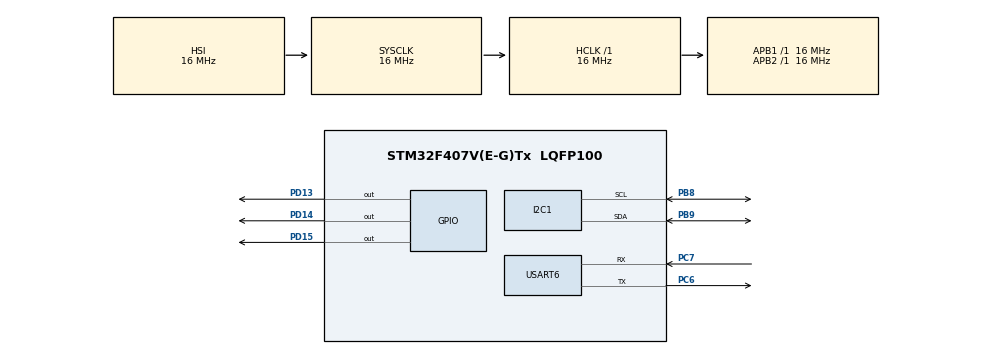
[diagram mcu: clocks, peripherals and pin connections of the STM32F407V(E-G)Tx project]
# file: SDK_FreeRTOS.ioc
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FREERTOS.Queues01=myKbdQueue,8,uint8_t,0,Dynamic,NULL,NULL
FREERTOS.Tasks01=Task_LED1,0,128,StartTaskLED1,Default,NULL,Dynamic,NULL,NULL;myTaskTetris,0,512,StartTaskTetris,Default,NULL,Dynamic,NULL,NULL;myTaskKbd,0,512,StartTaskKbd,Default,NULL,Dynamic,NULL,NULL
FREERTOS.configENABLE_BACKWARD_COMPATIBILITY=0
FREERTOS.configGENERATE_RUN_TIME_STATS=1
FREERTOS.configUSE_NEWLIB_REENTRANT=1
FREERTOS.configUSE_STATS_FORMATTING_FUNCTIONS=1
FREERTOS.configUSE_TRACE_FACILITY=1
Mcu.Family=STM32F4
Mcu.Name=STM32F407V(E-G)Tx
Mcu.Package=LQFP100
NVIC.PriorityGroup=NVIC_PRIORITYGROUP_4
NVIC.TIM1_UP_TIM10_IRQn=true\:0\:0\:false\:false\:true\:false\:false\:true\:true
NVIC.TimeBase=TIM1_UP_TIM10_IRQn
NVIC.TimeBaseIP=TIM1
PA13.Mode=JTAG_5_pins
PA13.Signal=SYS_JTMS-SWDIO
PA14.Mode=JTAG_5_pins
PA14.Signal=SYS_JTCK-SWCLK
PA15.Mode=JTAG_5_pins
PA15.Signal=SYS_JTDI
PB3.Mode=JTAG_5_pins
PB3.Signal=SYS_JTDO-SWO
PB4.Mode=JTAG_5_pins
PB4.Signal=SYS_JTRST
PB8.Mode=I2C
PB8.Signal=I2C1_SCL
PB9.Mode=I2C
PB9.Signal=I2C1_SDA
PC6.Mode=Asynchronous
PC6.Signal=USART6_TX
PC7.Mode=Asynchronous
PC7.Signal=USART6_RX
PD13.Signal=GPIO_Output
PD14.Signal=GPIO_Output
PD15.Signal=GPIO_Output
PH0-OSC_IN.Mode=HSE-External-Oscillator
PH0-OSC_IN.Signal=RCC_OSC_IN
PH1-OSC_OUT.Mode=HSE-External-Oscillator
PH1-OSC_OUT.Signal=RCC_OSC_OUT
ProjectManager.HeapSize=0x200
ProjectManager.StackSize=0x400
ProjectManager.TargetToolchain=STM32CubeIDE
RCC.AHBFreq_Value=16000000
RCC.APB1Freq_Value=16000000
RCC.APB2Freq_Value=16000000
RCC.CortexFreq_Value=16000000
RCC.HSE_VALUE=25000000
RCC.HSI_VALUE=16000000
RCC.LSE_VALUE=32768
RCC.SYSCLKFreq_VALUE=16000000
RCC.VCOOutputFreq_Value=192000000
USART6.VirtualMode=VM_ASYNC
VP_FREERTOS_VS_CMSIS_V1.Mode=CMSIS_V1
VP_RNG_VS_RNG.Mode=RNG_Activate
VP_SYS_VS_tim1.Mode=TIM1
board=custom

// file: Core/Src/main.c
/* USER CODE BEGIN Header */
/**
  ******************************************************************************
  * @file           : main.c
  * @brief          : Main program body
  ******************************************************************************
  * This notice applies to any and all portions of this file
  * that are not between comment pairs USER CODE BEGIN and
  * USER CODE END. Other portions of this file, whether
  * inserted by the user or by software development tools
  * are owned by their respective copyright owners.
  *
  * Copyright (c) 2019 STMicroelectronics International N.V.
  * All rights reserved.
  *
  * Redistribution and use in source and binary forms, with or without
  * modification, are permitted, provided that the following conditions are met:
  *
  * 1. Redistribution of source code must retain the above copyright notice,
  *    this list of conditions and the following disclaimer.
  * 2. Redistributions in binary form must reproduce the above copyright notice,
  *    this list of conditions and the following disclaimer in the documentation
  *    and/or other materials provided with the distribution.
  * 3. Neither the name of STMicroelectronics nor the names of other
  *    contributors to this software may be used to endorse or promote products
  *    derived from this software without specific written permission.
  * 4. This software, including modifications and/or derivative works of this
  *    software, must execute solely and exclusively on microcontroller or
  *    microprocessor devices manufactured by or for STMicroelectronics.
  * 5. Redistribution and use of this software other than as permitted under
  *    this license is void and will automatically terminate your rights under
  *    this license.
  *
  * THIS SOFTWARE IS PROVIDED BY STMICROELECTRONICS AND CONTRIBUTORS "AS IS"
  * AND ANY EXPRESS, IMPLIED OR STATUTORY WARRANTIES, INCLUDING, BUT NOT
  * LIMITED TO, THE IMPLIED WARRANTIES OF MERCHANTABILITY, FITNESS FOR A
  * PARTICULAR PURPOSE AND NON-INFRINGEMENT OF THIRD PARTY INTELLECTUAL PROPERTY
  * RIGHTS ARE DISCLAIMED TO THE FULLEST EXTENT PERMITTED BY LAW. IN NO EVENT
  * SHALL STMICROELECTRONICS OR CONTRIBUTORS BE LIABLE FOR ANY DIRECT, INDIRECT,
  * INCIDENTAL, SPECIAL, EXEMPLARY, OR CONSEQUENTIAL DAMAGES (INCLUDING, BUT NOT
  * LIMITED TO, PROCUREMENT OF SUBSTITUTE GOODS OR SERVICES; LOSS OF USE, DATA,
  * OR PROFITS; OR BUSINESS INTERRUPTION) HOWEVER CAUSED AND ON ANY THEORY OF
  * LIABILITY, WHETHER IN CONTRACT, STRICT LIABILITY, OR TORT (INCLUDING
  * NEGLIGENCE OR OTHERWISE) ARISING IN ANY WAY OUT OF THE USE OF THIS SOFTWARE,
  * EVEN IF ADVISED OF THE POSSIBILITY OF SUCH DAMAGE.
  *
  ******************************************************************************
  */
/* USER CODE END Header */
#include "main.h"
#include "cmsis_os.h"
#include "i2c.h"
#include "rng.h"
#include "usart.h"
#include "gpio.h"

/* USER CODE BEGIN Includes */
#include "oled.h"
/* USER CODE END Includes */

void SystemClock_Config(void);
void MX_FREERTOS_Init(void);

int main(void)
{

  /* MCU Configuration--------------------------------------------------------*/

  /* Reset of all peripherals, Initializes the Flash interface and the Systick. */
  HAL_Init();

  /* Configure the system clock */
  SystemClock_Config();

  /* Initialize all configured peripherals */
  MX_GPIO_Init();
  MX_I2C1_Init();
  MX_USART6_UART_Init();
  MX_RNG_Init();
  /* USER CODE BEGIN 2 */
  oled_Init();

  oled_Fill(Black);
  oled_UpdateScreen();
  /* USER CODE END 2 */

  /* Call init function for freertos objects (in cmsis_os2.c) */
  MX_FREERTOS_Init();

  /* Start scheduler */
  osKernelStart();

  /* We should never get here as control is now taken by the scheduler */

  /* Infinite loop */
  while (1)
  {

  }
}

void SystemClock_Config(void)
{
  RCC_OscInitTypeDef RCC_OscInitStruct = {0};
  RCC_ClkInitTypeDef RCC_ClkInitStruct = {0};

  /** Configure the main internal regulator output voltage
  */
  __HAL_RCC_PWR_CLK_ENABLE();
  __HAL_PWR_VOLTAGESCALING_CONFIG(PWR_REGULATOR_VOLTAGE_SCALE1);

  /** Initializes the RCC Oscillators according to the specified parameters
  * in the RCC_OscInitTypeDef structure.
  */
  RCC_OscInitStruct.OscillatorType = RCC_OSCILLATORTYPE_HSI;
  RCC_OscInitStruct.HSIState = RCC_HSI_ON;
  RCC_OscInitStruct.HSICalibrationValue = RCC_HSICALIBRATION_DEFAULT;
  RCC_OscInitStruct.PLL.PLLState = RCC_PLL_ON;
  RCC_OscInitStruct.PLL.PLLSource = RCC_PLLSOURCE_HSI;
  RCC_OscInitStruct.PLL.PLLM = 16;
  RCC_OscInitStruct.PLL.PLLN = 192;
  RCC_OscInitStruct.PLL.PLLP = RCC_PLLP_DIV2;
  RCC_OscInitStruct.PLL.PLLQ = 4;
  if (HAL_RCC_OscConfig(&RCC_OscInitStruct) != HAL_OK)
  {
    Error_Handler();
  }

  /** Initializes the CPU, AHB and APB buses clocks
  */
  RCC_ClkInitStruct.ClockType = RCC_CLOCKTYPE_HCLK|RCC_CLOCKTYPE_SYSCLK
                              |RCC_CLOCKTYPE_PCLK1|RCC_CLOCKTYPE_PCLK2;
  RCC_ClkInitStruct.SYSCLKSource = RCC_SYSCLKSOURCE_HSI;
  RCC_ClkInitStruct.AHBCLKDivider = RCC_SYSCLK_DIV1;
  RCC_ClkInitStruct.APB1CLKDivider = RCC_HCLK_DIV1;
  RCC_ClkInitStruct.APB2CLKDivider = RCC_HCLK_DIV1;

  if (HAL_RCC_ClockConfig(&RCC_ClkInitStruct, FLASH_LATENCY_0) != HAL_OK)
  {
    Error_Handler();
  }
}

void HAL_TIM_PeriodElapsedCallback(TIM_HandleTypeDef *htim)
{
  if (htim->Instance == TIM1)
  {
    HAL_IncTick();
  }
}

void Error_Handler(void)
{
}

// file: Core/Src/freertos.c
/* USER CODE BEGIN Header */
/**
  ******************************************************************************
  * File Name          : freertos.c
  * Description        : Code for freertos applications
  ******************************************************************************
  * This notice applies to any and all portions of this file
  * that are not between comment pairs USER CODE BEGIN and
  * USER CODE END. Other portions of this file, whether
  * inserted by the user or by software development tools
  * are owned by their respective copyright owners.
  *
  * Copyright (c) 2019 STMicroelectronics International N.V.
  * All rights reserved.
  *
  * Redistribution and use in source and binary forms, with or without
  * modification, are permitted, provided that the following conditions are met:
  *
  * 1. Redistribution of source code must retain the above copyright notice,
  *    this list of conditions and the following disclaimer.
  * 2. Redistributions in binary form must reproduce the above copyright notice,
  *    this list of conditions and the following disclaimer in the documentation
  *    and/or other materials provided with the distribution.
  * 3. Neither the name of STMicroelectronics nor the names of other
  *    contributors to this software may be used to endorse or promote products
  *    derived from this software without specific written permission.
  * 4. This software, including modifications and/or derivative works of this
  *    software, must execute solely and exclusively on microcontroller or
  *    microprocessor devices manufactured by or for STMicroelectronics.
  * 5. Redistribution and use of this software other than as permitted under
  *    this license is void and will automatically terminate your rights under
  *    this license.
  *
  * THIS SOFTWARE IS PROVIDED BY STMICROELECTRONICS AND CONTRIBUTORS "AS IS"
  * AND ANY EXPRESS, IMPLIED OR STATUTORY WARRANTIES, INCLUDING, BUT NOT
  * LIMITED TO, THE IMPLIED WARRANTIES OF MERCHANTABILITY, FITNESS FOR A
  * PARTICULAR PURPOSE AND NON-INFRINGEMENT OF THIRD PARTY INTELLECTUAL PROPERTY
  * RIGHTS ARE DISCLAIMED TO THE FULLEST EXTENT PERMITTED BY LAW. IN NO EVENT
  * SHALL STMICROELECTRONICS OR CONTRIBUTORS BE LIABLE FOR ANY DIRECT, INDIRECT,
  * INCIDENTAL, SPECIAL, EXEMPLARY, OR CONSEQUENTIAL DAMAGES (INCLUDING, BUT NOT
  * LIMITED TO, PROCUREMENT OF SUBSTITUTE GOODS OR SERVICES; LOSS OF USE, DATA,
  * OR PROFITS; OR BUSINESS INTERRUPTION) HOWEVER CAUSED AND ON ANY THEORY OF
  * LIABILITY, WHETHER IN CONTRACT, STRICT LIABILITY, OR TORT (INCLUDING
  * NEGLIGENCE OR OTHERWISE) ARISING IN ANY WAY OUT OF THE USE OF THIS SOFTWARE,
  * EVEN IF ADVISED OF THE POSSIBILITY OF SUCH DAMAGE.
  *
  ******************************************************************************
  */
/* USER CODE END Header */

#include "FreeRTOS.h"
#include "task.h"
#include "main.h"
#include "cmsis_os.h"

/* USER CODE BEGIN Includes */
#include "usart.h"
#include <string.h>
#include "tetris_task.h"
#include "kbd_task.h"
/* USER CODE END Includes */

osThreadId Task_LED1Handle;
osThreadId myTaskTetrisHandle;
osThreadId myTaskKbdHandle;
osMessageQId myKbdQueueHandle;

void StartTaskLED1(void const * argument);
void StartTaskTetris(void const * argument);
void StartTaskKbd(void const * argument);

void MX_FREERTOS_Init(void); /* (MISRA C 2004 rule 8.1) */

/* GetIdleTaskMemory prototype (linked to static allocation support) */
void vApplicationGetIdleTaskMemory( StaticTask_t **ppxIdleTaskTCBBuffer, StackType_t **ppxIdleTaskStackBuffer, uint32_t *pulIdleTaskStackSize );

/* Hook prototypes */
void configureTimerForRunTimeStats(void);
unsigned long getRunTimeCounterValue(void);

/* USER CODE BEGIN 1 */
/* Functions needed when configGENERATE_RUN_TIME_STATS is on */
__weak void configureTimerForRunTimeStats(void)
{

}

__weak unsigned long getRunTimeCounterValue(void)
{
return 0;
}
/* USER CODE END 1 */

/* USER CODE BEGIN GET_IDLE_TASK_MEMORY */
static StaticTask_t xIdleTaskTCBBuffer;
static StackType_t xIdleStack[configMINIMAL_STACK_SIZE];

void vApplicationGetIdleTaskMemory( StaticTask_t **ppxIdleTaskTCBBuffer, StackType_t **ppxIdleTaskStackBuffer, uint32_t *pulIdleTaskStackSize )
{
  *ppxIdleTaskTCBBuffer = &xIdleTaskTCBBuffer;
  *ppxIdleTaskStackBuffer = &xIdleStack[0];
  *pulIdleTaskStackSize = configMINIMAL_STACK_SIZE;
  /* place for user code */
}
/* USER CODE END GET_IDLE_TASK_MEMORY */

void MX_FREERTOS_Init(void) {

  /* Create the queue(s) */
  /* definition and creation of myKbdQueue */
  osMessageQDef(myKbdQueue, 8, uint8_t);
  myKbdQueueHandle = osMessageCreate(osMessageQ(myKbdQueue), NULL);

  /* Create the thread(s) */
  /* definition and creation of Task_LED1 */
  osThreadDef(Task_LED1, StartTaskLED1, osPriorityNormal, 0, 128);
  Task_LED1Handle = osThreadCreate(osThread(Task_LED1), NULL);

  /* definition and creation of myTaskTetris */
  osThreadDef(myTaskTetris, StartTaskTetris, osPriorityNormal, 0, 512);
  myTaskTetrisHandle = osThreadCreate(osThread(myTaskTetris), NULL);

  /* definition and creation of myTaskKbd */
  osThreadDef(myTaskKbd, StartTaskKbd, osPriorityNormal, 0, 512);
  myTaskKbdHandle = osThreadCreate(osThread(myTaskKbd), NULL);

}

void StartTaskLED1(void const * argument)
{
  /* USER CODE BEGIN StartTaskLED1 */
  /* Infinite loop */
  for(;;)
  {
	  HAL_GPIO_TogglePin(GPIOD, GPIO_PIN_15);
	  osDelay(600);
  }
  /* USER CODE END StartTaskLED1 */
}

void StartTaskTetris(void const * argument)
{
  /* USER CODE BEGIN StartTaskTetris */
  /* Infinite loop */
	Tetris_Task(argument);
  /* USER CODE END StartTaskTetris */
}

void StartTaskKbd(void const * argument)
{
  /* USER CODE BEGIN StartTaskKbd */
  /* Infinite loop */
	Kbd_Task(argument);
  /* USER CODE END StartTaskKbd */
}
